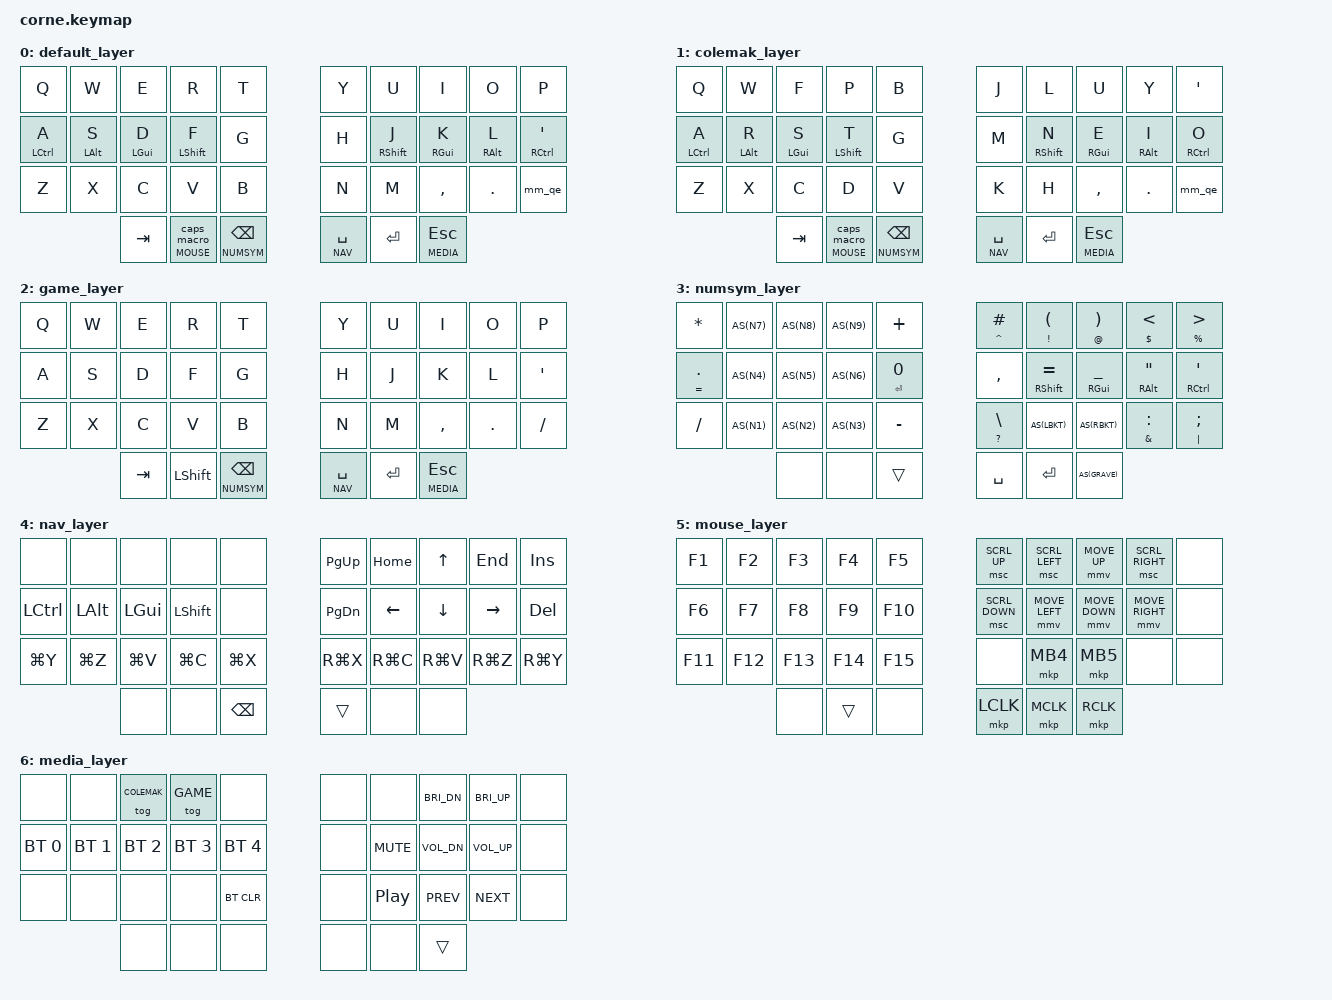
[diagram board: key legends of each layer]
/*
 * Copyright (c) 2020 The ZMK Contributors
 *
 * SPDX-License-Identifier: MIT
 */

#define ZMK_POINTING_DEFAULT_MOVE_VAL 1000
#define ZMK_POINTING_DEFAULT_SCRL_VAL 20

#include <behaviors.dtsi>
#include <dt-bindings/zmk/keys.h>
#include <dt-bindings/zmk/bt.h>
#include <dt-bindings/zmk/pointing.h>


#define DEFAULT 0
#define COLEMAK 1
#define GAME    2
#define NUMSYM  3
#define NAV     4
#define MOUSE   5
#define MEDIA   6

#define AS(keycode) &ht LS(keycode) keycode


&lt {
    flavor = "balanced";
    tapping-term-ms = <200>;
    quick-tap-ms = <200>;
};

&sk {
    release-after-ms = <900>;
    quick-release;
};


/ {
    chosen {
        zmk,physical-layout = &foostan_corne_5col_layout;
    };

    macros {
        caps_macro: caps_macro {
            compatible = "zmk,behavior-macro";
            #binding-cells = <0>;
            bindings = <&kp CAPS>;
            tap-ms = <100>;
        };
    };

    behaviors {
        lt_caps: lt_caps {
            compatible = "zmk,behavior-hold-tap";
            flavor = "tap-preferred";
            #binding-cells = <2>;
            bindings = <&mo>, <&caps_macro>;
            tapping-term-ms = <200>;
        };

        hml: homerow_mod_left {
            compatible = "zmk,behavior-hold-tap";
            flavor = "balanced";
            #binding-cells = <2>;
            bindings = <&kp>, <&kp>;
            tapping-term-ms = <280>;
            quick-tap-ms = <175>;
            require-prior-idle-ms = <150>;
            hold-trigger-key-positions = <5 6 7 8 9 15 16 17 18 19 25 26 27 28 29 33 34 35>;
            hold-trigger-on-release;
        };

        hmr: homerow_mod_right {
            compatible = "zmk,behavior-hold-tap";
            flavor = "balanced";
            #binding-cells = <2>;
            bindings = <&kp>, <&kp>;
            tapping-term-ms = <280>;
            quick-tap-ms = <175>;
            require-prior-idle-ms = <150>;
            hold-trigger-key-positions = <0 1 2 3 4 10 11 12 13 14 20 21 22 23 24 30 31 32>;
            hold-trigger-on-release;
        };

        ht: hold_tap {
            compatible = "zmk,behavior-hold-tap";
            flavor = "balanced";
            #binding-cells = <2>;
            bindings = <&kp>, <&kp>;
            tapping-term-ms = <200>;
            quick-tap-ms = <200>;
        };

        mm_sft: mod_morph_shift {
            compatible = "zmk,behavior-mod-morph";
            #binding-cells = <0>;
            bindings = <&sk LSHIFT>, <&caps_word>;
            mods = <(MOD_LSFT)>;
        };

        ht_mm_sft: hold_tap_mod_morph_shift {
            compatible = "zmk,behavior-hold-tap";
            flavor = "balanced";
            #binding-cells = <2>;
            bindings = <&mo>, <&mm_sft>;
            tapping-term-ms = <200>;
            quick-tap-ms = <200>;
        };

        mm_st: mod_morph_space_tab {
            compatible = "zmk,behavior-mod-morph";
            #binding-cells = <0>;
            bindings = <&kp SPACE>, <&kp TAB>;
            mods = <(MOD_RSFT)>; 
        };

        ht_mm_st: hold_tap_mod_morph_space_tab {
            compatible = "zmk,behavior-hold-tap";
            flavor = "balanced";
            #binding-cells = <2>;
            bindings = <&mo>, <&mm_st>;
            tapping-term-ms = <200>;
            quick-tap-ms = <200>;
        };

        mm_bd: mod_morph_backspace_delete {
            compatible = "zmk,behavior-mod-morph";
            #binding-cells = <0>;
            bindings = <&kp BSPC>, <&kp DEL>;
            mods = <(MOD_LSFT)>; 
        };

        ht_mm_bd: hold_tap_mod_morph_backspace_delete {
            compatible = "zmk,behavior-hold-tap";
            flavor = "balanced";
            #binding-cells = <2>;
            bindings = <&mo>, <&mm_bd>;
            tapping-term-ms = <200>;
            quick-tap-ms = <200>;
        };

        mm_cu: mod_morph_comma_underscore {
            compatible = "zmk,behavior-mod-morph";
            #binding-cells = <0>;
            bindings = <&kp COMMA>, <&kp UNDER>;
            mods = <(MOD_LSFT)>; 
        };

        mm_dm: mod_morph_dot_minus {
            compatible = "zmk,behavior-mod-morph";
            #binding-cells = <0>;
            bindings = <&kp DOT>, <&kp MINUS>;
            mods = <(MOD_LSFT)>; 
        };

        mm_qe: mod_morph_qmark_exclamation {
            compatible = "zmk,behavior-mod-morph";
            #binding-cells = <0>;
            bindings = <&kp QMARK>, <&kp EXCL>;
            mods = <(MOD_LSFT)>; 
        };
    };
    
    keymap {
        compatible = "zmk,keymap";

        default_layer {
// -----------------------------------------------------------------------------------------
// |  Q  |  W  |  E  |  R  |  T  |     |  Y  |  U  |  I  |  O  |  P  |
// |  A  |  S  |  D  |  F  |  G  |     |  H  |  J  |  K  |  L  |  '  |
// |  Z  |  X  |  C  |  V  |  B  |     |  N  |  M  |  ,  |  .  |  ?  |
//             | TAB |CAPS | BSP |     | SPC | RET | ESC |
            bindings = <
    &kp Q          &kp W          &kp E          &kp R          &kp T             &kp Y          &kp U          &kp I          &kp O          &kp P
    &hml LCTRL A   &hml LALT S    &hml LGUI D    &hml LSHIFT F  &kp G             &kp H          &hmr RSHIFT J  &hmr RGUI K    &hmr RALT L    &hmr RCTRL SQT
    &kp Z          &kp X          &kp C          &kp V          &kp B             &kp N          &kp M          &kp COMMA      &kp DOT        &mm_qe
                                  &kp TAB   &lt_caps MOUSE 0   &lt NUMSYM BSPC    &lt NAV SPACE  &kp RET        &lt MEDIA ESC
            >;
        };

        colemak_layer {
// -----------------------------------------------------------------------------------------
// |  Q  |  W  |  F  |  P  |  B  |     |  J  |  L  |  U  |  Y  |  '  |
// |  A  |  R  |  S  |  T  |  G  |     |  M  |  N  |  E  |  I  |  O  |
// |  Z  |  X  |  C  |  D  |  V  |     |  K  |  H  |  ,  |  .  |  ?  |
//             | TAB |CAPS | BSP |     | SPC | RET | ESC |
            bindings = <
    &kp Q          &kp W          &kp F          &kp P          &kp B             &kp J          &kp L          &kp U          &kp Y          &kp SQT
    &hml LCTRL A   &hml LALT R    &hml LGUI S    &hml LSHIFT T  &kp G             &kp M          &hmr RSHIFT N  &hmr RGUI E    &hmr RALT I    &hmr RCTRL O
    &kp Z          &kp X          &kp C          &kp D          &kp V             &kp K          &kp H          &kp COMMA      &kp DOT        &mm_qe
                                  &kp TAB   &lt_caps MOUSE 0   &lt NUMSYM BSPC    &lt NAV SPACE  &kp RET        &lt MEDIA ESC
            >;
        };

        game_layer {
// -----------------------------------------------------------------------------------------
// |  Q  |  W  |  E  |  R  |  T  |     |  Y  |  U  |  I  |  O  |  P  |
// |  A  |  S  |  D  |  F  |  G  |     |  H  |  J  |  K  |  L  |  '  |
// |  Z  |  X  |  C  |  V  |  B  |     |  N  |  M  |  ,  |  .  |  /  |
//             | TAB | SFT | BSP |     | SPC | RET | ESC |
            bindings = <
    &kp Q          &kp W          &kp E          &kp R          &kp T             &kp Y          &kp U          &kp I          &kp O          &kp P
    &kp A          &kp S          &kp D          &kp F          &kp G             &kp H          &kp J          &kp K          &kp L          &kp SQT
    &kp Z          &kp X          &kp C          &kp V          &kp B             &kp N          &kp M          &kp COMMA      &kp DOT        &kp FSLH
                                  &kp TAB        &kp LSHIFT     &lt NUMSYM BSPC   &lt NAV SPACE  &kp RET        &lt MEDIA ESC
            >;
        };

        numsym_layer {
// -----------------------------------------------------------------------------------------
// |  *  |  7  |  8  |  9  |  +  |     |  #  |  (  |  )  |  <  |  >  |
// |  .  |  4  |  5  |  6  |  0  |     |  ,  |  =  |  _  |  "  |  '  |
// |  /  |  1  |  2  |  3  |  -  |     |  \  |  [  |  ]  |  :  |  ;  |
//             |     |     |trans|     | SPC | RET |  `  |
            bindings = <
    &kp STAR       AS(N7)         AS(N8)         AS(N9)         &kp PLUS        &ht CARET HASH  &ht EXCL LPAR   &ht AT RPAR    &ht DLLR LT    &ht PRCNT GT
    &ht EQUAL DOT  AS(N4)         AS(N5)         AS(N6)         &ht RET N0      &kp COMMA  &hmr RSHIFT EQUAL  &hmr RGUI UNDER  &hmr RALT DQT  &hmr RCTRL SQT
    &kp FSLH       AS(N1)         AS(N2)         AS(N3)         &kp MINUS        &ht QMARK BSLH  AS(LBKT)       AS(RBKT)      &ht AMPS COLON  &ht PIPE SEMI
                                  &none          &none          &trans            &kp SPACE      &kp RET        AS(GRAVE)
            >;
        };

        nav_layer {
// -----------------------------------------------------------------------------------------
// |     |     |     |     |     |     |PG_UP|HOME | UP  | END | INS |
// |CTRL | ALT | GUI |SHFT |     |     |PG_DN|LEFT |DOWN |RIGHT| DEL |
// |REDO |UNDO | PST | CPY | CUT |     | CUT | CPY | PST |UNDO |REDO |
//             |     |     | BSP |     |trans|     |     |
            bindings = <
    &none          &none          &none          &none          &none             &kp PG_UP      &kp HOME       &kp UP         &kp END        &kp INS
    &kp LCTRL      &kp LALT       &kp LGUI       &kp LSHIFT     &none             &kp PG_DN      &kp LEFT       &kp DOWN       &kp RIGHT      &kp DEL
    &kp LG(Y)      &kp LG(Z)      &kp LG(V)      &kp LG(C)      &kp LG(X)         &kp RG(X)      &kp RG(C)      &kp RG(V)      &kp RG(Z)      &kp RG(Y)
                                  &none          &none          &kp BSPC          &trans         &none          &none
            >;
        };

        mouse_layer {
// -----------------------------------------------------------------------------------------
// | F1  | F2  | F3  | F4  | F5  |     |SC_UP|SC_L | MUP |SC_R |     |
// | F6  | F7  | F8  | F9  | F10 |     |SC_DN|MLEFT|MDOWN|MRGHT|     |
// | F11 | F12 | F13 | F14 | F15 |     |     | MB4 | MB5 |     |     |
//             |     |trans|     |     |LCLK |MCLK |RCLK |
            bindings = <
    &kp F1         &kp F2         &kp F3         &kp F4         &kp F5         &msc SCRL_UP  &msc SCRL_LEFT  &mmv MOVE_UP    &msc SCRL_RIGHT  &none
    &kp F6         &kp F7         &kp F8         &kp F9         &kp F10      &msc SCRL_DOWN  &mmv MOVE_LEFT  &mmv MOVE_DOWN  &mmv MOVE_RIGHT  &none
    &kp F11        &kp F12        &kp F13        &kp F14        &kp F15           &none          &mkp MB4       &mkp MB5       &none          &none
                                  &none          &trans         &none             &mkp LCLK      &mkp MCLK      &mkp RCLK
            >;
        };

        media_layer {
// -----------------------------------------------------------------------------------------
// |     |     | CMK |GAME |     |     |     |     |DP_DN|DP_UP|     |
// | BT1 | BT2 | BT3 | BT4 | BT5 |     |     |MUTE |V_DN |V_UP |     |
// |     |     |     |     |BTCLR|     |     | P/P |PREV |NEXT |     |
//             |     |     |     |     |     |     |trans|
            bindings = <
    &none          &none          &tog COLEMAK   &tog GAME      &none             &none          &none          &kp C_BRI_DN   &kp C_BRI_UP   &none
    &bt BT_SEL 0   &bt BT_SEL 1   &bt BT_SEL 2   &bt BT_SEL 3   &bt BT_SEL 4      &none          &kp C_MUTE     &kp C_VOL_DN   &kp C_VOL_UP   &none
    &none          &none          &none          &none          &bt BT_CLR        &none          &kp C_PP       &kp C_PREV     &kp C_NEXT     &none
                                  &none          &none          &none             &none          &none          &trans
            >;
        };
    };
};
